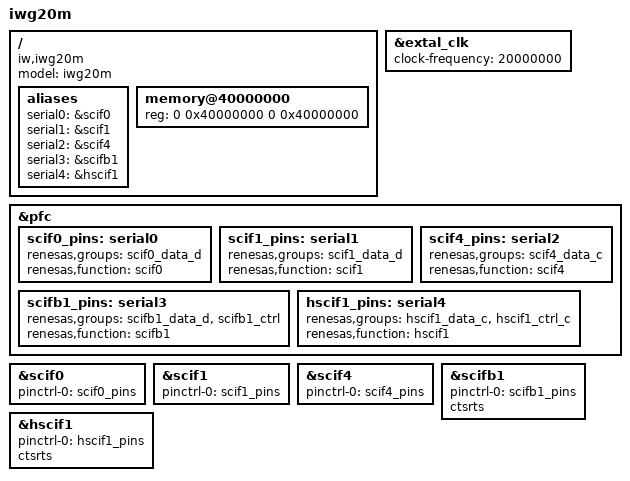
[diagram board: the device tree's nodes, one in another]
/*
 * Copyright (c) 2015 iWave Systems Technologies Pvt. Ltd.
 *
 * The code contained herein is licensed under the GNU General Public
 * License. You may obtain a copy of the GNU General Public License
 * Version 2 or later at the following locations:
 *
 * http://www.opensource.org/licenses/gpl-license.html
 * http://www.gnu.org/copyleft/gpl.html
 */

/dts-v1/;
#include "r8a7744.dtsi"

/ {
	model = "iwg20m";
	compatible = "iw,iwg20m", "renesas,r8a7744";
	aliases {
		serial0 = &scif0;
		serial1 = &scif1;
		serial2 = &scif4;
		serial3 = &scifb1;
		serial4 = &hscif1;
	};
	memory@40000000 {
		device_type = "memory";
		reg = <0 0x40000000 0 0x40000000>;
	};
};

&extal_clk {
	clock-frequency = <20000000>;
};

&pfc {
	scif0_pins: serial0 {
		renesas,groups = "scif0_data_d";
		renesas,function = "scif0";
	};

	scif1_pins: serial1 {
		renesas,groups = "scif1_data_d";
		renesas,function = "scif1";
	};

	scif4_pins: serial2 {
		renesas,groups = "scif4_data_c";
		renesas,function = "scif4";
	};

	scifb1_pins: serial3 {
		renesas,groups = "scifb1_data_d", "scifb1_ctrl";
		renesas,function = "scifb1";
	};

	hscif1_pins: serial4 {
		renesas,groups = "hscif1_data_c", "hscif1_ctrl_c";
		renesas,function = "hscif1";
	};
};

&scif0 {
	pinctrl-0 = <&scif0_pins>;
	pinctrl-names = "default";

	status = "okay";
};

&scif1 {
	pinctrl-0 = <&scif1_pins>;
	pinctrl-names = "default";

	status = "okay";
};

&scif4 {
	pinctrl-0 = <&scif4_pins>;
	pinctrl-names = "default";

	status = "okay";
};

&scifb1 {
	pinctrl-0 = <&scifb1_pins>;
	pinctrl-names = "default";
	ctsrts;

	status = "okay";
};

&hscif1 {
	pinctrl-0 = <&hscif1_pins>;
	pinctrl-names = "default";
	ctsrts;

	status = "okay";
};




